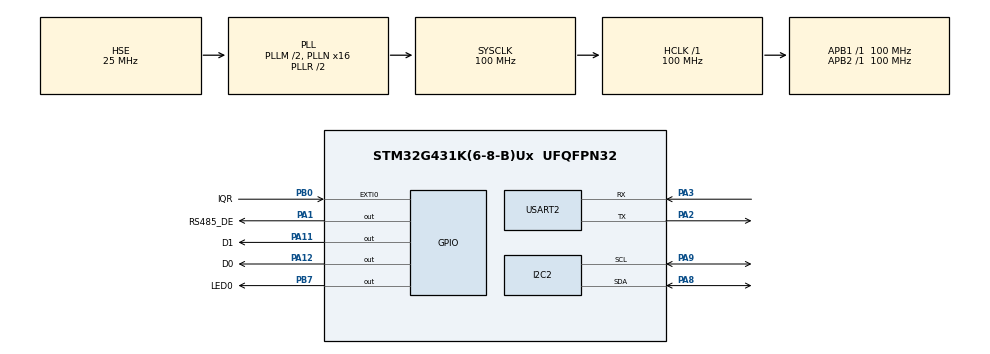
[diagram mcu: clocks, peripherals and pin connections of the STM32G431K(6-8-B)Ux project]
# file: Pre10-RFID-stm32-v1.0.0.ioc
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Dma.Request0=USART2_RX
Dma.Request1=USART2_TX
Dma.USART2_RX.0.Direction=DMA_PERIPH_TO_MEMORY
Dma.USART2_RX.0.EventEnable=DISABLE
Dma.USART2_RX.0.Instance=DMA1_Channel1
Dma.USART2_RX.0.MemDataAlignment=DMA_MDATAALIGN_BYTE
Dma.USART2_RX.0.MemInc=DMA_MINC_ENABLE
Dma.USART2_RX.0.Mode=DMA_NORMAL
Dma.USART2_RX.0.PeriphDataAlignment=DMA_PDATAALIGN_BYTE
Dma.USART2_RX.0.PeriphInc=DMA_PINC_DISABLE
Dma.USART2_RX.0.Polarity=HAL_DMAMUX_REQ_GEN_RISING
Dma.USART2_RX.0.Priority=DMA_PRIORITY_LOW
Dma.USART2_RX.0.RequestNumber=1
Dma.USART2_RX.0.SignalID=NONE
Dma.USART2_RX.0.SyncEnable=DISABLE
Dma.USART2_RX.0.SyncPolarity=HAL_DMAMUX_SYNC_NO_EVENT
Dma.USART2_RX.0.SyncRequestNumber=1
Dma.USART2_RX.0.SyncSignalID=NONE
Dma.USART2_TX.1.Direction=DMA_MEMORY_TO_PERIPH
Dma.USART2_TX.1.EventEnable=DISABLE
Dma.USART2_TX.1.Instance=DMA1_Channel2
Dma.USART2_TX.1.MemDataAlignment=DMA_MDATAALIGN_BYTE
Dma.USART2_TX.1.MemInc=DMA_MINC_ENABLE
Dma.USART2_TX.1.Mode=DMA_NORMAL
Dma.USART2_TX.1.PeriphDataAlignment=DMA_PDATAALIGN_BYTE
Dma.USART2_TX.1.PeriphInc=DMA_PINC_DISABLE
Dma.USART2_TX.1.Polarity=HAL_DMAMUX_REQ_GEN_RISING
Dma.USART2_TX.1.Priority=DMA_PRIORITY_LOW
Dma.USART2_TX.1.RequestNumber=1
Dma.USART2_TX.1.SignalID=NONE
Dma.USART2_TX.1.SyncEnable=DISABLE
Dma.USART2_TX.1.SyncPolarity=HAL_DMAMUX_SYNC_NO_EVENT
Dma.USART2_TX.1.SyncRequestNumber=1
Dma.USART2_TX.1.SyncSignalID=NONE
I2C2.Timing=0x20B182BE
Mcu.Family=STM32G4
Mcu.Name=STM32G431K(6-8-B)Ux
Mcu.Package=UFQFPN32
NVIC.DMA1_Channel1_IRQn=true\:0\:0\:false\:false\:true\:false\:true\:true
NVIC.DMA1_Channel2_IRQn=true\:0\:0\:false\:false\:true\:false\:true\:true
NVIC.EXTI0_IRQn=true\:1\:0\:true\:false\:true\:true\:true\:true
NVIC.PriorityGroup=NVIC_PRIORITYGROUP_4
NVIC.USART2_IRQn=true\:2\:0\:true\:false\:true\:true\:true\:true
PA1.GPIO_Label=RS485_DE
PA1.GPIO_Speed=GPIO_SPEED_FREQ_MEDIUM
PA1.Signal=GPIO_Output
PA11.GPIO_Label=D1
PA11.GPIO_ModeDefaultOutputPP=GPIO_MODE_OUTPUT_OD
PA11.GPIO_PuPd=GPIO_NOPULL
PA11.GPIO_Speed=GPIO_SPEED_FREQ_HIGH
PA11.Signal=GPIO_Output
PA12.GPIO_Label=D0
PA12.GPIO_ModeDefaultOutputPP=GPIO_MODE_OUTPUT_OD
PA12.GPIO_PuPd=GPIO_NOPULL
PA12.GPIO_Speed=GPIO_SPEED_FREQ_HIGH
PA12.Signal=GPIO_Output
PA13.Mode=Serial_Wire
PA13.Signal=SYS_JTMS-SWDIO
PA14.Mode=Serial_Wire
PA14.Signal=SYS_JTCK-SWCLK
PA2.Mode=Asynchronous
PA2.Signal=USART2_TX
PA3.Mode=Asynchronous
PA3.Signal=USART2_RX
PA8.Mode=I2C
PA8.Signal=I2C2_SDA
PA9.Mode=I2C
PA9.Signal=I2C2_SCL
PB0.GPIO_Label=IQR
PB0.GPIO_ModeDefaultEXTI=GPIO_MODE_IT_FALLING
PB0.GPIO_PuPd=GPIO_PULLUP
PB0.Signal=GPXTI0
PB7.GPIO_Label=LED0
PB7.Signal=GPIO_Output
PF0-OSC_IN.Mode=HSE-External-Oscillator
PF0-OSC_IN.Signal=RCC_OSC_IN
PF1-OSC_OUT.Mode=HSE-External-Oscillator
PF1-OSC_OUT.Signal=RCC_OSC_OUT
ProjectManager.HeapSize=0x200
ProjectManager.StackSize=0x400
ProjectManager.TargetToolchain=CMake
RCC.ADC12Freq_Value=100000000
RCC.AHBFreq_Value=100000000
RCC.APB1Freq_Value=100000000
RCC.APB1TimFreq_Value=100000000
RCC.APB2Freq_Value=100000000
RCC.APB2TimFreq_Value=100000000
RCC.CortexFreq_Value=100000000
RCC.EXTERNAL_CLOCK_VALUE=12288000
RCC.HCLKFreq_Value=100000000
RCC.HSE_VALUE=25000000
RCC.HSI48_VALUE=48000000
RCC.HSI_VALUE=16000000
RCC.LSE_VALUE=32768
RCC.PLLM=RCC_PLLM_DIV2
RCC.PLLN=16
RCC.PLLSourceVirtual=RCC_PLLSOURCE_HSE
RCC.SYSCLKFreq_VALUE=100000000
RCC.SYSCLKSource=RCC_SYSCLKSOURCE_PLLCLK
RCC.USBFreq_Value=100000000
RCC.VCOOutputFreq_Value=200000000
USART2.VirtualMode-Asynchronous=VM_ASYNC
VP_SYS_VS_DBSignals.Mode=DisableDeadBatterySignals
board=custom

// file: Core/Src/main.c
/* USER CODE BEGIN Header */
/**
  ******************************************************************************
  * @file           : main.c
  * @brief          : Main program body
  ******************************************************************************
  * @attention
  *
  * Copyright (c) 2026 STMicroelectronics.
  * All rights reserved.
  *
  * This software is licensed under terms that can be found in the LICENSE file
  * in the root directory of this software component.
  * If no LICENSE file comes with this software, it is provided AS-IS.
  *
  ******************************************************************************
  */
/* USER CODE END Header */
#include "main.h"
#include "dma.h"
#include "i2c.h"
#include "usart.h"
#include "gpio.h"

/* USER CODE BEGIN Includes */
#include "app_task.h"
/* USER CODE END Includes */

void SystemClock_Config(void);

int main(void)
{

  /* MCU Configuration--------------------------------------------------------*/

  /* Reset of all peripherals, Initializes the Flash interface and the Systick. */
  HAL_Init();

  /* Configure the system clock */
  SystemClock_Config();

  /* Initialize all configured peripherals */
  MX_GPIO_Init();
  MX_DMA_Init();
  MX_I2C2_Init();
  MX_USART2_UART_Init();
  /* USER CODE BEGIN 2 */
   task();
  /* USER CODE END 2 */

  /* Infinite loop */
  while (1)
  {

  }
}

void SystemClock_Config(void)
{
  RCC_OscInitTypeDef RCC_OscInitStruct = {0};
  RCC_ClkInitTypeDef RCC_ClkInitStruct = {0};

  /** Configure the main internal regulator output voltage
  */
  HAL_PWREx_ControlVoltageScaling(PWR_REGULATOR_VOLTAGE_SCALE1);

  /** Initializes the RCC Oscillators according to the specified parameters
  * in the RCC_OscInitTypeDef structure.
  */
  RCC_OscInitStruct.OscillatorType = RCC_OSCILLATORTYPE_HSE;
  RCC_OscInitStruct.HSEState = RCC_HSE_ON;
  RCC_OscInitStruct.PLL.PLLState = RCC_PLL_ON;
  RCC_OscInitStruct.PLL.PLLSource = RCC_PLLSOURCE_HSE;
  RCC_OscInitStruct.PLL.PLLM = RCC_PLLM_DIV2;
  RCC_OscInitStruct.PLL.PLLN = 16;
  RCC_OscInitStruct.PLL.PLLP = RCC_PLLP_DIV2;
  RCC_OscInitStruct.PLL.PLLQ = RCC_PLLQ_DIV2;
  RCC_OscInitStruct.PLL.PLLR = RCC_PLLR_DIV2;
  if (HAL_RCC_OscConfig(&RCC_OscInitStruct) != HAL_OK)
  {
    Error_Handler();
  }

  /** Initializes the CPU, AHB and APB buses clocks
  */
  RCC_ClkInitStruct.ClockType = RCC_CLOCKTYPE_HCLK|RCC_CLOCKTYPE_SYSCLK
                              |RCC_CLOCKTYPE_PCLK1|RCC_CLOCKTYPE_PCLK2;
  RCC_ClkInitStruct.SYSCLKSource = RCC_SYSCLKSOURCE_PLLCLK;
  RCC_ClkInitStruct.AHBCLKDivider = RCC_SYSCLK_DIV1;
  RCC_ClkInitStruct.APB1CLKDivider = RCC_HCLK_DIV1;
  RCC_ClkInitStruct.APB2CLKDivider = RCC_HCLK_DIV1;

  if (HAL_RCC_ClockConfig(&RCC_ClkInitStruct, FLASH_LATENCY_3) != HAL_OK)
  {
    Error_Handler();
  }
}

void Error_Handler(void)
{
  __disable_irq();
  while (1)
  {
  }
}
